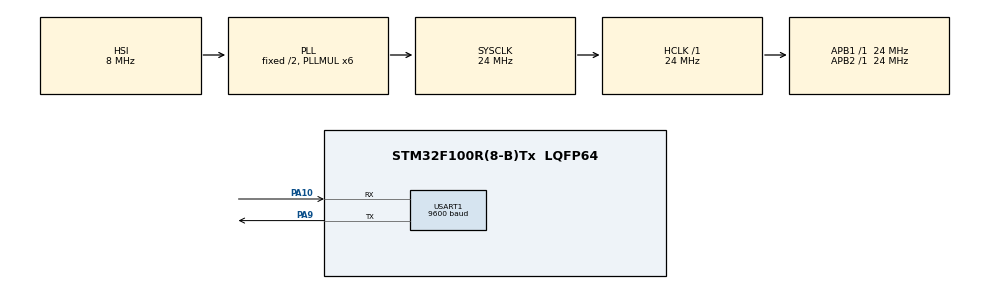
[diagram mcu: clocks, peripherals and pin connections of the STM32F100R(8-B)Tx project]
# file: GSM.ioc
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Dma.Request0=USART1_TX
Dma.USART1_TX.0.Direction=DMA_MEMORY_TO_PERIPH
Dma.USART1_TX.0.Instance=DMA1_Channel4
Dma.USART1_TX.0.MemDataAlignment=DMA_MDATAALIGN_BYTE
Dma.USART1_TX.0.MemInc=DMA_MINC_ENABLE
Dma.USART1_TX.0.Mode=DMA_NORMAL
Dma.USART1_TX.0.PeriphDataAlignment=DMA_PDATAALIGN_BYTE
Dma.USART1_TX.0.PeriphInc=DMA_PINC_DISABLE
Dma.USART1_TX.0.Priority=DMA_PRIORITY_MEDIUM
Mcu.Family=STM32F1
Mcu.Name=STM32F100R(8-B)Tx
Mcu.Package=LQFP64
NVIC.DMA1_Channel4_IRQn=true\:1\:0\:true\:false\:true\:false\:true
NVIC.PriorityGroup=NVIC_PRIORITYGROUP_4
NVIC.USART1_IRQn=true\:1\:0\:true\:false\:true\:true\:true
PA10.Mode=Asynchronous
PA10.Signal=USART1_RX
PA13.Mode=Serial_Wire
PA13.Signal=SYS_JTMS-SWDIO
PA14.Mode=Serial_Wire
PA14.Signal=SYS_JTCK-SWCLK
PA9.Mode=Asynchronous
PA9.Signal=USART1_TX
ProjectManager.HeapSize=0x200
ProjectManager.StackSize=0x400
ProjectManager.TargetToolchain=STM32CubeIDE
RCC.AHBFreq_Value=24000000
RCC.APB1Freq_Value=24000000
RCC.APB1TimFreq_Value=24000000
RCC.APB2Freq_Value=24000000
RCC.APB2TimFreq_Value=24000000
RCC.HCLKFreq_Value=24000000
RCC.PLLMUL=RCC_PLL_MUL6
RCC.SYSCLKFreq_VALUE=24000000
RCC.SYSCLKSource=RCC_SYSCLKSOURCE_PLLCLK
USART1.BaudRate=9600
USART1.VirtualMode=VM_ASYNC
board=custom

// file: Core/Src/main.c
/* USER CODE BEGIN Header */
/**
  ******************************************************************************
  * @file           : main.c
  * @brief          : Main program body
  ******************************************************************************
  * @attention
  *
  * Copyright (c) 2022 STMicroelectronics.
  * All rights reserved.
  *
  * This software is licensed under terms that can be found in the LICENSE file
  * in the root directory of this software component.
  * If no LICENSE file comes with this software, it is provided AS-IS.
  *
  ******************************************************************************
  */
/* USER CODE END Header */
#include "main.h"

/* USER CODE BEGIN Includes */

#include "DRV_CFG.h"
#include "ESP8266DRV07.h"

#define GSM_BUF_SIZE 300

char GSM_BUF[GSM_BUF_SIZE] = {0};
uint16_t GSM_READ_COUNT = 0;

void GSM_USART_CALLBACK()
{
	GSM_BUF[GSM_READ_COUNT] = LL_USART_ReceiveData8(USART1);

   if(GSM_READ_COUNT < GSM_BUF_SIZE)
    {
	   GSM_READ_COUNT++;
    }
}

void GSM_SEND(char *DATA, uint16_t size)
{
	LL_DMA_DisableChannel(ESP8266_DMA, ESP8266_DMA_CHANEL);
	LL_DMA_ConfigAddresses(ESP8266_DMA, ESP8266_DMA_CHANEL, (uint32_t)DATA, LL_USART_DMA_GetRegAddr(ESP8266_USART), LL_DMA_DIRECTION_MEMORY_TO_PERIPH);
	LL_DMA_SetDataLength(ESP8266_DMA, ESP8266_DMA_CHANEL, size);
	LL_DMA_EnableChannel(ESP8266_DMA, ESP8266_DMA_CHANEL);

	while(DMA_TC != 1){};

}
/* USER CODE END Includes */

void SystemClock_Config(void);
static void MX_GPIO_Init(void);
static void MX_USART1_UART_Init(void);
static void MX_DMA_Init(void);

int main(void)
{

  /* MCU Configuration--------------------------------------------------------*/

  /* Reset of all peripherals, Initializes the Flash interface and the Systick. */
  HAL_Init();

  /* Configure the system clock */
  SystemClock_Config();

  /* Initialize all configured peripherals */
  MX_GPIO_Init();
  MX_USART1_UART_Init();
  MX_DMA_Init();
  /* USER CODE BEGIN 2 */

  //  LL_DMA_EnableIT_TC(DMA1, LL_DMA_CHANNEL_4);
  LL_USART_Enable(USART1);
  NVIC_EnableIRQ(USART1_IRQn);

  USART_DMA_ACTIVE();

  //LL_USART_EnableIT_RXNE(USART1);
  //LL_USART_EnableDMAReq_TX(USART1);

  GSM_SEND("AT00000000",10);
  /* USER CODE END 2 */

  /* Infinite loop */
  while (1)
  {

  }
}

void SystemClock_Config(void)
{
  RCC_OscInitTypeDef RCC_OscInitStruct = {0};
  RCC_ClkInitTypeDef RCC_ClkInitStruct = {0};

  /** Initializes the RCC Oscillators according to the specified parameters
  * in the RCC_OscInitTypeDef structure.
  */
  RCC_OscInitStruct.OscillatorType = RCC_OSCILLATORTYPE_HSI;
  RCC_OscInitStruct.HSIState = RCC_HSI_ON;
  RCC_OscInitStruct.HSICalibrationValue = RCC_HSICALIBRATION_DEFAULT;
  RCC_OscInitStruct.PLL.PLLState = RCC_PLL_ON;
  RCC_OscInitStruct.PLL.PLLSource = RCC_PLLSOURCE_HSI_DIV2;
  RCC_OscInitStruct.PLL.PLLMUL = RCC_PLL_MUL6;
  if (HAL_RCC_OscConfig(&RCC_OscInitStruct) != HAL_OK)
  {
    Error_Handler();
  }
  /** Initializes the CPU, AHB and APB buses clocks
  */
  RCC_ClkInitStruct.ClockType = RCC_CLOCKTYPE_HCLK|RCC_CLOCKTYPE_SYSCLK
                              |RCC_CLOCKTYPE_PCLK1|RCC_CLOCKTYPE_PCLK2;
  RCC_ClkInitStruct.SYSCLKSource = RCC_SYSCLKSOURCE_PLLCLK;
  RCC_ClkInitStruct.AHBCLKDivider = RCC_SYSCLK_DIV1;
  RCC_ClkInitStruct.APB1CLKDivider = RCC_HCLK_DIV1;
  RCC_ClkInitStruct.APB2CLKDivider = RCC_HCLK_DIV1;

  if (HAL_RCC_ClockConfig(&RCC_ClkInitStruct, FLASH_LATENCY_0) != HAL_OK)
  {
    Error_Handler();
  }
}

static void MX_USART1_UART_Init(void)
{

  LL_USART_InitTypeDef USART_InitStruct = {0};

  LL_GPIO_InitTypeDef GPIO_InitStruct = {0};

  /* Peripheral clock enable */
  LL_APB2_GRP1_EnableClock(LL_APB2_GRP1_PERIPH_USART1);

  LL_APB2_GRP1_EnableClock(LL_APB2_GRP1_PERIPH_GPIOA);
  /**USART1 GPIO Configuration
  PA9   ------> USART1_TX
  PA10   ------> USART1_RX
  */
  GPIO_InitStruct.Pin = LL_GPIO_PIN_9;
  GPIO_InitStruct.Mode = LL_GPIO_MODE_ALTERNATE;
  GPIO_InitStruct.Speed = LL_GPIO_SPEED_FREQ_HIGH;
  GPIO_InitStruct.OutputType = LL_GPIO_OUTPUT_PUSHPULL;
  LL_GPIO_Init(GPIOA, &GPIO_InitStruct);

  GPIO_InitStruct.Pin = LL_GPIO_PIN_10;
  GPIO_InitStruct.Mode = LL_GPIO_MODE_FLOATING;
  LL_GPIO_Init(GPIOA, &GPIO_InitStruct);

  /* USART1 DMA Init */

  /* USART1_TX Init */
  LL_DMA_SetDataTransferDirection(DMA1, LL_DMA_CHANNEL_4, LL_DMA_DIRECTION_MEMORY_TO_PERIPH);

  LL_DMA_SetChannelPriorityLevel(DMA1, LL_DMA_CHANNEL_4, LL_DMA_PRIORITY_MEDIUM);

  LL_DMA_SetMode(DMA1, LL_DMA_CHANNEL_4, LL_DMA_MODE_NORMAL);

  LL_DMA_SetPeriphIncMode(DMA1, LL_DMA_CHANNEL_4, LL_DMA_PERIPH_NOINCREMENT);

  LL_DMA_SetMemoryIncMode(DMA1, LL_DMA_CHANNEL_4, LL_DMA_MEMORY_INCREMENT);

  LL_DMA_SetPeriphSize(DMA1, LL_DMA_CHANNEL_4, LL_DMA_PDATAALIGN_BYTE);

  LL_DMA_SetMemorySize(DMA1, LL_DMA_CHANNEL_4, LL_DMA_MDATAALIGN_BYTE);

  /* USART1 interrupt Init */
  NVIC_SetPriority(USART1_IRQn, NVIC_EncodePriority(NVIC_GetPriorityGrouping(),1, 0));
  NVIC_EnableIRQ(USART1_IRQn);

  USART_InitStruct.BaudRate = 9600;
  USART_InitStruct.DataWidth = LL_USART_DATAWIDTH_8B;
  USART_InitStruct.StopBits = LL_USART_STOPBITS_1;
  USART_InitStruct.Parity = LL_USART_PARITY_NONE;
  USART_InitStruct.TransferDirection = LL_USART_DIRECTION_TX_RX;
  USART_InitStruct.HardwareFlowControl = LL_USART_HWCONTROL_NONE;
  USART_InitStruct.OverSampling = LL_USART_OVERSAMPLING_16;
  LL_USART_Init(USART1, &USART_InitStruct);
  LL_USART_ConfigAsyncMode(USART1);
  LL_USART_Enable(USART1);

}

static void MX_DMA_Init(void)
{

  /* DMA controller clock enable */
  __HAL_RCC_DMA1_CLK_ENABLE();

  /* DMA interrupt init */
  /* DMA1_Channel4_IRQn interrupt configuration */
  NVIC_SetPriority(DMA1_Channel4_IRQn, NVIC_EncodePriority(NVIC_GetPriorityGrouping(),1, 0));
  NVIC_EnableIRQ(DMA1_Channel4_IRQn);

}

static void MX_GPIO_Init(void)
{

  /* GPIO Ports Clock Enable */
  __HAL_RCC_GPIOA_CLK_ENABLE();

}

void Error_Handler(void)
{
  __disable_irq();
  while (1)
  {
  }
}
